# CH583SFR register map
Vendor: WCH Ltd.; Series: CH58x; File version: 1.1
CPU: RISC-V r0p0, little endian, no MPU, no FPU, 2 interrupt priority bits
Registers are 8-bit, read-write, reset 0x0 unless marked. A register's access mark holds for its fields unless they carry their own. Offsets are from the block's base; [hi:lo] are bit positions.

## TMR2 — Timer2 register
Base 0x40002800
0x00 CTRL_MOD reset 0x2 — RW, TMR2 mode control
  [7:6] PWM_REPEAT — RW, timer PWM repeat mode: 00=1, 01=4, 10=8, 11-16
  [7:6] CAP_EDGE — RW, timer capture edge mode: 00=disable, 01=edge change, 10=fall to fall, 11-rise to rise
  [4] OUT_POLAR — RW, timer PWM output polarity: 0=default low and high action, 1=default high and low action
  [4] CAP_COUNT — RW, count sub-mode if RB_TMR_MODE_IN=1: 0=capture, 1=count
  [3] OUT_EN — RW, timer output enable
  [2] COUNT_EN — RW, timer count enable
  [1] ALL_CLEAR — RW, force clear timer FIFO and count
  [0] MODE_IN — RW, timer in mode: 0=timer_PWM, 1=capture_count
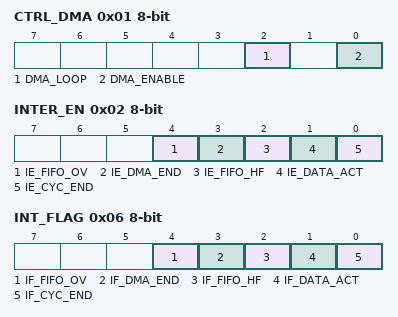
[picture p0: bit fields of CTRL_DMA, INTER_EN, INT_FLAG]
0x01 CTRL_DMA — RW, TMR2 DMA control
  [2] DMA_LOOP — RW, timer1_2 DMA address loop enable
  [0] DMA_ENABLE — RW, timer1_2 DMA enable
0x02 INTER_EN — RW, TMR2 interrupt enable
  [4] IE_FIFO_OV — RW, enable interrupt for timer FIFO overflow
  [3] IE_DMA_END — RW, enable interrupt for timer1/2 DMA completion
  [2] IE_FIFO_HF — RW, enable interrupt for timer FIFO half (capture fifo >=4 or PWM fifo less than 3)
  [1] IE_DATA_ACT — RW, enable interrupt for timer capture input action or PWM trigger
  [0] IE_CYC_END — RW, enable interrupt for timer capture count timeout or PWM cycle end
0x06 INT_FLAG — RW1, TMR2 interrupt flag
  [4] IF_FIFO_OV — RW1, interrupt flag for timer FIFO overflow
  [3] IF_DMA_END — RW1, interrupt flag for timer1/2 DMA completion
  [2] IF_FIFO_HF — RW1, interrupt flag for timer FIFO half (capture fifo >=4 or PWM fifo less than 3
  [1] IF_DATA_ACT — RW1, interrupt flag for timer capture input action or PWM trigger
  [0] IF_CYC_END — RW1, interrupt flag for timer capture count timeout or PWM cycle end
0x07 FIFO_COUNT ro (reset mask 0xF0) — RO, TMR2 FIFO count status
  [7:0] FIFO_COUNT — RW, TMR2 FIFO count status
0x08 COUNT 32-bit ro (reset mask 0xF0) — RO, TMR2 current count
  [31:0] COUNT — RW, TMR2 current count
0x0C CNT_END 32-bit (reset mask 0xF0) — RW, TMR2 end count value, only low 26 bit
  [31:0] CNT_END — RW, TMR2 current count
0x10 FIFO 32-bit — RO, TMR2 FIFO register, only low 26 bit
  [31:0] FIFO — RW, TMR2 current count
0x14 DMA_NOW 16-bit ro — RO, TMR2 DMA current address
  [15:0] DMA_NOW — RW, TMR2 current count
0x18 DMA_BEG 16-bit — RW, TMR2 DMA begin address
0x1C DMA_END 16-bit — RW, TMR2 DMA end address

## SPI0
Base 0x40004000
0x00 CTRL_MOD reset 0x2 — RW, SPI0 mode control
  [7] MISO_OE — RW, SPI MISO output enable
  [6] MOSI_OE — RW, SPI MOSI output enable
  [5] SCK_OE — RW, SPI SCK output enable
  [4] FIFO_DIR — RW, SPI FIFO direction: 0=out(write @master mode), 1=in(read @master mode)
  [3] MST_SCK_MOD — RW, SPI master clock mode: 0=mode 0, 1=mode 3
  [3] SLV_CMD_MOD — RW, SPI0 slave command mode: 0=byte stream, 1=first byte command
  [2] TWO_WIRE_MOD — RW, SPI0 enable 2 wire mode for slave: 0=3wire(SCK0,MOSI,MISO), 1=2wire(SCK0,MISO=MXSX)
  [1] ALL_CLEAR — RW, force clear SPI FIFO and count
  [0] MODE_SLAVE — RW, SPI0 slave mode: 0=master or host, 1=slave or device
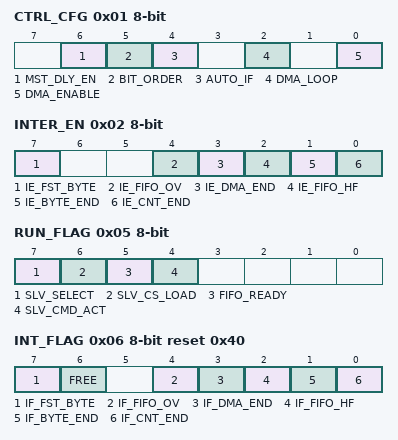
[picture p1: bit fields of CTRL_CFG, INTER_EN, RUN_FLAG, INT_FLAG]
0x01 CTRL_CFG — RW, SPI0 configuration control
  [6] MST_DLY_EN — RW, SPI master input delay enable
  [5] BIT_ORDER — RW, SPI bit data order: 0=MSB first, 1=LSB first
  [4] AUTO_IF — RW, enable buffer/FIFO accessing to auto clear RB_SPI_IF_BYTE_END interrupt flag
  [2] DMA_LOOP — RW, SPI0 DMA address loop enable
  [0] DMA_ENABLE — RW, SPI0 DMA enable
0x02 INTER_EN — RW, SPI0 interrupt enable
  [7] IE_FST_BYTE — RW, enable interrupt for SPI0 slave mode first byte received
  [4] IE_FIFO_OV — RW, enable interrupt for SPI0 FIFO overflow
  [3] IE_DMA_END — RW, enable interrupt for SPI0 DMA completion
  [2] IE_FIFO_HF — RW, enable interrupt for SPI FIFO half
  [1] IE_BYTE_END — RW, enable interrupt for SPI byte exchanged
  [0] IE_CNT_END — RW, enable interrupt for SPI total byte count end
0x03 CLOCK_DIV reset 0x10 — RW, SPI0 master clock divisor
0x03 SLAVE_PRE reset 0x10 — RW, SPI0 slave preset value
0x04 BUFFER — RW, SPI0 data buffer
0x05 RUN_FLAG ro — RO, SPI0 work flag
  [7] SLV_SELECT — RO, SPI0 slave selection status
  [6] SLV_CS_LOAD — RO, SPI0 slave chip-select loading status
  [5] FIFO_READY — RO, SPI FIFO ready status
  [4] SLV_CMD_ACT — RO, SPI0 slave first byte or command flag
0x06 INT_FLAG reset 0x40 — RW1, SPI0 interrupt flag
  [7] IF_FST_BYTE — RW1, interrupt flag for SPI0 slave mode first byte received
  [6] FREE — RO, current SPI free status
  [4] IF_FIFO_OV — RW1, interrupt flag for SPI0 FIFO overflow
  [3] IF_DMA_END — RW1, interrupt flag for SPI0 DMA completion
  [2] IF_FIFO_HF — RW1, interrupt flag for SPI FIFO half
  [1] IF_BYTE_END — RW1, interrupt flag for SPI byte exchanged
  [0] IF_CNT_END — RW1, interrupt flag for SPI total byte count end
0x07 FIFO_COUNT ro — RO, SPI0 FIFO count status
0x0C TOTAL_CNT 16-bit — RW, SPI0 total byte count, only low 12 bit
0x10 FIFO — RO/WO, SPI0 FIFO register
0x13 FIFO_COUNT1 ro — RO, SPI0 FIFO count status
0x14 DMA_NOW 16-bit — RW, SPI0 DMA current address
0x18 DMA_BEG 16-bit — RW, SPI0 DMA begin address
0x1C DMA_END 16-bit — RW, SPI0 DMA end address
